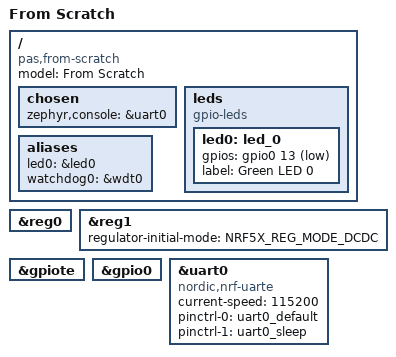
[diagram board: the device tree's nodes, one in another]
/dts-v1/;
#include <nordic/nrf52840_qiaa.dtsi>
#include <nordic/nrf52840_partition.dtsi>
#include "from_scratch-pinctrl.dtsi"

/ {
	model = "From Scratch";
	compatible = "pas,from-scratch";

	chosen {
		zephyr,console = &uart0;
	};

	leds {
		compatible = "gpio-leds";

		led0: led_0 {
			gpios = <&gpio0 13 GPIO_ACTIVE_LOW>;
			label = "Green LED 0";
		};
	};

	aliases {
		led0 = &led0;
		watchdog0 = &wdt0;
	};
};

&reg0 {
	status = "okay";
};

&reg1 {
	regulator-initial-mode = <NRF5X_REG_MODE_DCDC>;
};

&gpiote {
	status = "okay";
};

&gpio0 {
	status = "okay";
};

&uart0 {
	compatible = "nordic,nrf-uarte";
	status = "okay";
	current-speed = <115200>;
	pinctrl-0 = <&uart0_default>;
	pinctrl-1 = <&uart0_sleep>;
	pinctrl-names = "default", "sleep";
};
